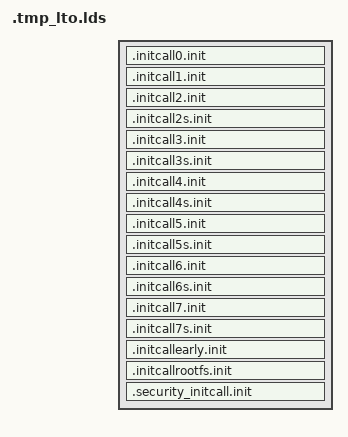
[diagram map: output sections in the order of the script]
SECTIONS {
	.initcall0.init : {
		*(.initcall0.init..69_53_init_mmap_min_addr) ;
		*(.initcall0.init..73_1865_dcc_init) ;
		*(.initcall0.init..66_347_mem_dump_init) ;
		*(.initcall0.init..71_947_init_watchdog) ;
		*(.initcall0.init..72_739_msm_restart_init) ;
		*(.initcall0.init..72_105_init_cpufreq_transition_notifier_list) ;
		*(.initcall0.init..150_868_net_ns_init) ;
	}
	.initcall1.init : {
		*(.initcall1.init..59_459_fpsimd_init) ;
		*(.initcall1.init..65_1789_enable_mrs_emulation) ;
		*(.initcall1.init..75_652_armv8_deprecated_init) ;
		*(.initcall1.init..87_953_arm64_memory_hotplug_init) ;
		*(.initcall1.init..81_1378_alloc_frozen_cpus) ;
		*(.initcall1.init..82_1425_cpu_hotplug_pm_sync_init) ;
		*(.initcall1.init..174_5366_wq_sysfs_init) ;
		*(.initcall1.init..69_271_ksysfs_init) ;
		*(.initcall1.init..66_794_pm_init) ;
		*(.initcall1.init..73_236_rcu_set_runtime_mode) ;
		*(.initcall1.init..85_813_rcu_spawn_tasks_kthread) ;
		*(.initcall1.init..60_101_init_jiffies_clocksource) ;
		*(.initcall1.init..116_4203_futex_init) ;
		*(.initcall1.init..219_5468_cgroup_wq_init) ;
		*(.initcall1.init..85_1299_cgroup1_wq_init) ;
		*(.initcall1.init..50_215_cpu_pm_init) ;
		*(.initcall1.init..68_194_cma_init_reserved_areas) ;
		*(.initcall1.init..79_395_fsnotify_init) ;
		*(.initcall1.init..138_2842_filelock_init) ;
		*(.initcall1.init..53_167_init_script_binfmt) ;
		*(.initcall1.init..87_2396_init_elf_binfmt) ;
		*(.initcall1.init..87_2396_init_compat_elf_binfmt) ;
		*(.initcall1.init..81_174_configfs_init) ;
		*(.initcall1.init..85_871_debugfs_init) ;
		*(.initcall1.init..44_481_prandom_init_early) ;
		*(.initcall1.init..116_2289_pinctrl_init) ;
		*(.initcall1.init..92_3696_gpiolib_dev_init) ;
		*(.initcall1.init..70_1041_rpm_smd_clk_init) ;
		*(.initcall1.init..97_4916_regulator_init) ;
		*(.initcall1.init..89_1814_iommu_init) ;
		*(.initcall1.init..55_249_opp_debug_init) ;
		*(.initcall1.init..65_437_dma_init_reserved_memory) ;
		*(.initcall1.init..57_183_soc_bus_register) ;
		*(.initcall1.init..67_541_register_cpufreq_notifier) ;
		*(.initcall1.init..92_2674_cpufreq_core_init) ;
		*(.initcall1.init..73_832_cpuidle_init) ;
		*(.initcall1.init..164_2684_sock_init) ;
		*(.initcall1.init..149_3118_net_inuse_init) ;
		*(.initcall1.init..135_337_net_defaults_init) ;
		*(.initcall1.init..138_1290_init_default_flow_dissectors) ;
		*(.initcall1.init..180_2777_netlink_proto_init) ;
	}
	.initcall2.init : {
		*(.initcall2.init..71_148_debug_monitors_init) ;
		*(.initcall2.init..70_362_topology_init) ;
		*(.initcall2.init..75_820_schedtune_init) ;
		*(.initcall2.init..72_298_irq_sysfs_init) ;
		*(.initcall2.init..102_7222_init_per_zone_wmark_min) ;
		*(.initcall2.init..88_242_bdi_class_init) ;
		*(.initcall2.init..76_197_mm_sysfs_init) ;
		*(.initcall2.init..82_961_ramoops_init) ;
		*(.initcall2.init..70_831_gpiolib_sysfs_init) ;
		*(.initcall2.init..70_111_pcibus_class_init) ;
		*(.initcall2.init..115_1507_pci_driver_init) ;
		*(.initcall2.init..89_675_backlight_class_init) ;
		*(.initcall2.init..77_210_amba_init) ;
		*(.initcall2.init..57_124_msm_bus_init) ;
		*(.initcall2.init..67_366_qsee_irq_init) ;
		*(.initcall2.init..66_297_regulator_stub_init) ;
		*(.initcall2.init..107_3277_tty_class_init) ;
		*(.initcall2.init..65_50_iommu_dev_init) ;
		*(.initcall2.init..58_1160_mipi_dsi_bus_init) ;
		*(.initcall2.init..86_1211_wakeup_sources_debugfs_init) ;
		*(.initcall2.init..58_2930_regmap_initcall) ;
		*(.initcall2.init..66_253_syscon_init) ;
		*(.initcall2.init..138_3629_spi_init) ;
		*(.initcall2.init..57_599_spmi_init) ;
		*(.initcall2.init..70_1293_spmi_sim_init) ;
		*(.initcall2.init..61_191_slimbus_init) ;
		*(.initcall2.init..102_1778_i2c_init) ;
		*(.initcall2.init..59_444_teo_governor_init) ;
		*(.initcall2.init..90_1609_init_lpm) ;
		*(.initcall2.init..65_129_qcom_apcs_ipc_init) ;
		*(.initcall2.init..64_173_qcom_hwspinlock_init) ;
		*(.initcall2.init..77_597_rpmsg_init) ;
		*(.initcall2.init..79_575_rpmsg_char_init) ;
		*(.initcall2.init..69_349_glink_rpm_init) ;
		*(.initcall2.init..159_2013_qrtr_proto_init) ;
		*(.initcall2.init..127_644_kobject_uevent_init) ;
	}
	.initcall2s.init : {
		*(.initcall2s.init..66_257_of_iommu_init) ;
		*(.initcall2s.init..74_1650_msm_rpm_driver_init) ;
	}
	.initcall3.init : {
		*(.initcall3.init..79_383_debug_traps_init) ;
		*(.initcall3.init..67_125_alloc_vectors_page) ;
		*(.initcall3.init..68_249_vdso_init) ;
		*(.initcall3.init..71_1045_arch_hw_breakpoint_init) ;
		*(.initcall3.init..65_688_arm64_dma_init) ;
		*(.initcall3.init..67_1036___iommu_dma_init) ;
		*(.initcall3.init..68_530_gic_init_sys) ;
		*(.initcall3.init..54_1585_trinket_pinctrl_init) ;
		*(.initcall3.init..67_353_dma_channel_table_init) ;
		*(.initcall3.init..108_1356_dma_bus_init) ;
		*(.initcall3.init..64_247_qcom_smd_rpm_init) ;
		*(.initcall3.init..66_1234_qcom_smem_init) ;
		*(.initcall3.init..59_354_qpnp_pbs_init) ;
		*(.initcall3.init..64_419_cmd_db_device_init) ;
		*(.initcall3.init..102_2014_subsys_restart_init) ;
		*(.initcall3.init..75_481_glink_probe_init) ;
		*(.initcall3.init..64_327_cx_ipeak_init) ;
		*(.initcall3.init..69_2327_qpnp_lcdb_regulator_init) ;
		*(.initcall3.init..66_184_refgen_init) ;
		*(.initcall3.init..74_2072_rpm_smd_regulator_driver_init) ;
		*(.initcall3.init..57_163_pmic_spmi_init) ;
		*(.initcall3.init..70_1386_spmi_pmic_arb_init) ;
		*(.initcall3.init..70_3095_sps_init) ;
		*(.initcall3.init..64_4596_gsi_init) ;
		*(.initcall3.init..125_3223_ipa3_usb_init) ;
		*(.initcall3.init..78_1051_qmp_init) ;
	}
	.initcall3s.init : {
		*(.initcall3s.init..67_255_deferred_probe_initcall) ;
		*(.initcall3s.init..69_525_of_platform_default_populate_init) ;
	}
	.initcall4.init : {
		*(.initcall4.init..53_232_uid_cache_init) ;
		*(.initcall4.init..65_958_param_sysfs_init) ;
		*(.initcall4.init..52_245_user_namespace_sysctl_init) ;
		*(.initcall4.init..74_306_sched_energy_init) ;
		*(.initcall4.init..53_156_cgroup_namespaces_init) ;
		*(.initcall4.init..119_420_dev_map_init) ;
		*(.initcall4.init..90_634_oom_init) ;
		*(.initcall4.init..89_259_default_bdi_init) ;
		*(.initcall4.init..76_2754_percpu_enable_async) ;
		*(.initcall4.init..94_2154_kcompactd_init) ;
		*(.initcall4.init..121_3753_init_user_reserve) ;
		*(.initcall4.init..122_3774_init_admin_reserve) ;
		*(.initcall4.init..123_3844_init_reserve_notifier) ;
		*(.initcall4.init..84_861_swap_init_sysfs) ;
		*(.initcall4.init..133_3787_swapfile_init) ;
		*(.initcall4.init..80_247_sel_ib_pkey_init) ;
		*(.initcall4.init..75_36_crypto_wq_init) ;
		*(.initcall4.init..119_296_cryptomgr_init) ;
		*(.initcall4.init..103_1397_cryptd_init) ;
		*(.initcall4.init..82_2223_init_bio) ;
		*(.initcall4.init..79_930_blk_settings_init) ;
		*(.initcall4.init..87_448_blk_ioc_init) ;
		*(.initcall4.init..80_181_blk_softirq_init) ;
		*(.initcall4.init..118_2972_blk_mq_init) ;
		*(.initcall4.init..88_1022_genhd_device_init) ;
		*(.initcall4.init..96_3835_gpiolib_debugfs_init) ;
		*(.initcall4.init..61_1108_pwm_debugfs_init) ;
		*(.initcall4.init..54_474_pwm_sysfs_init) ;
		*(.initcall4.init..79_414_pci_slot_init) ;
		*(.initcall4.init..97_1975_fbmem_init) ;
		*(.initcall4.init..67_1063_gdsc_init) ;
		*(.initcall4.init..65_1287_clk_cpu_osm_init) ;
		*(.initcall4.init..64_808_disp_cc_trinket_init) ;
		*(.initcall4.init..64_4454_gcc_trinket_init) ;
		*(.initcall4.init..64_489_gpu_cc_trinket_init) ;
		*(.initcall4.init..64_378_video_cc_trinket_init) ;
		*(.initcall4.init..65_124_cpuss_dump_init) ;
		*(.initcall4.init..60_1810_socinfo_init) ;
		*(.initcall4.init..25_381_msm_minidump_init) ;
		*(.initcall4.init..91_1707_msm_pil_init) ;
		*(.initcall4.init..65_679_mem_module_init) ;
		*(.initcall4.init..70_214_regulator_fixed_voltage_init) ;
		*(.initcall4.init..81_305_misc_init) ;
		*(.initcall4.init..104_5280_arm_smmu_init) ;
		*(.initcall4.init..83_1474_vga_arb_device_init) ;
		*(.initcall4.init..66_208_register_cpu_capacity_sysctl) ;
		*(.initcall4.init..58_347_qpnp_misc_init) ;
		*(.initcall4.init..86_638_dax_fs_init) ;
		*(.initcall4.init..69_1315_dma_buf_init) ;
		*(.initcall4.init..94_845_init_scsi) ;
		*(.initcall4.init..148_1986_phy_init) ;
		*(.initcall4.init..81_1330_usb_init) ;
		*(.initcall4.init..62_531_dual_role_class_init) ;
		*(.initcall4.init..71_383_usb_phy_generic_init) ;
		*(.initcall4.init..94_1641_usb_udc_init) ;
		*(.initcall4.init..100_1068_serio_init) ;
		*(.initcall4.init..118_2466_input_init) ;
		*(.initcall4.init..79_2489_qpnp_pon_init) ;
		*(.initcall4.init..67_474_rtc_init) ;
		*(.initcall4.init..67_329_media_devnode_init) ;
		*(.initcall4.init..78_1066_videodev_init) ;
		*(.initcall4.init..69_983_init_dvbdev) ;
		*(.initcall4.init..78_1869_rc_core_init) ;
		*(.initcall4.init..57_1121_power_supply_class_init) ;
		*(.initcall4.init..75_907_hwmon_init) ;
		*(.initcall4.init..86_4710_mmc_init) ;
		*(.initcall4.init..56_424_leds_init) ;
		*(.initcall4.init..64_469_qcom_scm_init) ;
		*(.initcall4.init..64_395_msm_ion_init) ;
		*(.initcall4.init..72_705_msm_ext_disp_init) ;
		*(.initcall4.init..79_2043_geni_se_driver_init) ;
		*(.initcall4.init..59_283_qpnp_revid_init) ;
		*(.initcall4.init..126_3990_ipa_module_init) ;
		*(.initcall4.init..83_1317_devfreq_init) ;
		*(.initcall4.init..54_151_devfreq_simple_ondemand_init) ;
		*(.initcall4.init..54_54_devfreq_performance_init) ;
		*(.initcall4.init..54_51_devfreq_powersave_init) ;
		*(.initcall4.init..56_154_devfreq_userspace_init) ;
		*(.initcall4.init..55_195_devfreq_passive_init) ;
		*(.initcall4.init..62_688_devfreq_cpufreq_init) ;
		*(.initcall4.init..72_631_msm_adreno_tz_init) ;
		*(.initcall4.init..54_125_devfreq_vbif_init) ;
		*(.initcall4.init..56_260_devfreq_gpubw_init) ;
		*(.initcall4.init..80_1859_iio_init) ;
		*(.initcall4.init..91_971_arm_pmu_hp_init) ;
		*(.initcall4.init..65_38_ras_init) ;
		*(.initcall4.init..64_1300_nvmem_init) ;
		*(.initcall4.init..54_196_sdam_init) ;
		*(.initcall4.init..57_64_init_soundcore) ;
		*(.initcall4.init..76_422_alsa_sound_init) ;
		*(.initcall4.init..151_3404_proto_init) ;
		*(.initcall4.init..280_8922_net_dev_init) ;
		*(.initcall4.init..149_3340_neigh_init) ;
		*(.initcall4.init..113_173_fib_notifier_init) ;
		*(.initcall4.init..176_1052_fib_rules_init) ;
		*(.initcall4.init..144_2088_pktsched_init) ;
		*(.initcall4.init..151_1062_tc_filter_init) ;
		*(.initcall4.init..141_1269_tc_action_init) ;
		*(.initcall4.init..128_1010_genl_init) ;
		*(.initcall4.init..138_203_ipv4_netfilter_init) ;
		*(.initcall4.init..155_2306_cipso_v4_init) ;
		*(.initcall4.init..139_838_bt_init) ;
		*(.initcall4.init..149_1397_cfg80211_init) ;
		*(.initcall4.init..106_408_wireless_nlevent_init) ;
		*(.initcall4.init..145_1537_netlbl_init) ;
		*(.initcall4.init..105_1358_rfkill_init) ;
	}
	.initcall4s.init : {
		*(.initcall4s.init..89_6852_pcie_init) ;
		*(.initcall4s.init..68_256_deferred_probe_initcall) ;
	}
	.initcall5.init : {
		*(.initcall5.init..70_72_create_debug_debugfs_entry) ;
		*(.initcall5.init..66_697_dma_debug_do_init) ;
		*(.initcall5.init..84_933_sugov_register) ;
		*(.initcall5.init..72_707_clocksource_done_booting) ;
		*(.initcall5.init..110_539_bpf_init) ;
		*(.initcall5.init..84_1243_init_pipe_fs) ;
		*(.initcall5.init..97_807_inotify_user_setup) ;
		*(.initcall5.init..169_2334_eventpoll_init) ;
		*(.initcall5.init..63_178_anon_inode_init) ;
		*(.initcall5.init..137_2818_proc_locks_init) ;
		*(.initcall5.init..95_3000_dquot_init) ;
		*(.initcall5.init..78_103_quota_init) ;
		*(.initcall5.init..51_64_proc_cmdline_init) ;
		*(.initcall5.init..73_112_proc_consoles_init) ;
		*(.initcall5.init..52_31_proc_cpuinfo_init) ;
		*(.initcall5.init..51_71_proc_devices_init) ;
		*(.initcall5.init..51_54_proc_interrupts_init) ;
		*(.initcall5.init..62_45_proc_loadavg_init) ;
		*(.initcall5.init..67_190_proc_meminfo_init) ;
		*(.initcall5.init..68_205_proc_stat_init) ;
		*(.initcall5.init..51_50_proc_uptime_init) ;
		*(.initcall5.init..51_35_proc_version_init) ;
		*(.initcall5.init..51_45_proc_softirqs_init) ;
		*(.initcall5.init..60_65_proc_kmsg_init) ;
		*(.initcall5.init..78_309_proc_page_init) ;
		*(.initcall5.init..79_277_init_ramfs_fs) ;
		*(.initcall5.init..89_764_blk_scsi_ioctl_init) ;
		*(.initcall5.init..64_736_clk_debug_trinket_init) ;
		*(.initcall5.init..73_460_mdss_pll_driver_init) ;
		*(.initcall5.init..77_1376_msm_bus_device_init_driver) ;
		*(.initcall5.init..101_962_chr_dev_init) ;
		*(.initcall5.init..86_1855_firmware_class_init) ;
		*(.initcall5.init..53_58_cpufreq_gov_performance_init) ;
		*(.initcall5.init..141_600_sysctl_core_init) ;
		*(.initcall5.init..136_526_eth_offload_init) ;
		*(.initcall5.init..146_1799_ipv4_offload_init) ;
		*(.initcall5.init..148_1929_inet_init) ;
		*(.initcall5.init..158_2984_af_unix_init) ;
		*(.initcall5.init..129_387_ipv6_offload_init) ;
	}
	.initcall5s.init : {
		*(.initcall5s.init..67_3739_pci_apply_final_quirks) ;
		*(.initcall5s.init..69_257_deferred_probe_initcall) ;
	}
	.initcall6.init : {
		*(.initcall6.init..71_391_register_kernel_offset_dumper) ;
		*(.initcall6.init..55_398_cpuinfo_regs_init) ;
		*(.initcall6.init..64_70_register_cpu_hwcaps_dumper) ;
		*(.initcall6.init..82_1316_armv8_pmu_driver_init) ;
		*(.initcall6.init..86_824_register_mem_limit_dumper) ;
		*(.initcall6.init..62_407_ptdump_init) ;
		*(.initcall6.init..88_126_cpu_feature_match_SHA1_init) ;
		*(.initcall6.init..88_156_cpu_feature_match_SHA2_init) ;
		*(.initcall6.init..112_602_ghash_ce_mod_init) ;
		*(.initcall6.init..85_240_crc32_pmull_mod_init) ;
		*(.initcall6.init..64_189_cpu_feature_match_AES_init) ;
		*(.initcall6.init..97_386_aes_mod_init) ;
		*(.initcall6.init..94_674_cpu_feature_match_AES_init) ;
		*(.initcall6.init..108_676_aes_init) ;
		*(.initcall6.init..93_185_sha256_mod_init) ;
		*(.initcall6.init..93_93_sha512_mod_init) ;
		*(.initcall6.init..81_122_chacha20_simd_mod_init) ;
		*(.initcall6.init..61_63_aes_init) ;
		*(.initcall6.init..91_477_aes_init) ;
		*(.initcall6.init..72_48_proc_execdomains_init) ;
		*(.initcall6.init..83_2318_cpuhp_sysfs_init) ;
		*(.initcall6.init..64_178_ioresources_init) ;
		*(.initcall6.init..68_200_irq_pm_init_ops) ;
		*(.initcall6.init..65_1761_timekeeping_init_ops) ;
		*(.initcall6.init..79_1061_init_clocksource_sysfs) ;
		*(.initcall6.init..64_398_init_timer_list_procfs) ;
		*(.initcall6.init..73_931_alarmtimer_init) ;
		*(.initcall6.init..73_284_init_posix_timers) ;
		*(.initcall6.init..79_762_clockevents_init_sysfs) ;
		*(.initcall6.init..59_319_sched_clock_syscore_init) ;
		*(.initcall6.init..109_710_kallsyms_init) ;
		*(.initcall6.init..63_92_ikconfig_init) ;
		*(.initcall6.init..119_1242_seccomp_sysctl_init) ;
		*(.initcall6.init..44_148_utsname_sysctl_init) ;
		*(.initcall6.init..264_11758_perf_event_sysfs_init) ;
		*(.initcall6.init..49_133_system_trusted_keyring_init) ;
		*(.initcall6.init..108_3874_kswapd_init) ;
		*(.initcall6.init..78_2131_extfrag_debug_init) ;
		*(.initcall6.init..75_185_mm_compute_batch_init) ;
		*(.initcall6.init..84_576_workingset_init) ;
		*(.initcall6.init..113_2892_proc_vmalloc_init) ;
		*(.initcall6.init..73_1788_memblock_init_debugfs) ;
		*(.initcall6.init..109_2845_procswaps_init) ;
		*(.initcall6.init..121_5932_slab_sysfs_init) ;
		*(.initcall6.init..100_2633_zs_init) ;
		*(.initcall6.init..75_1145_init_z3fold) ;
		*(.initcall6.init..83_252_process_reclaim_init) ;
		*(.initcall6.init..98_1034_fcntl_init) ;
		*(.initcall6.init..72_277_proc_filesystems_init) ;
		*(.initcall6.init..90_2077_start_dirtytime_writeback) ;
		*(.initcall6.init..82_467_blkdev_init) ;
		*(.initcall6.init..79_1472_dio_init) ;
		*(.initcall6.init..59_396_dnotify_init) ;
		*(.initcall6.init..86_274_aio_setup) ;
		*(.initcall6.init..91_488_fscrypt_init) ;
		*(.initcall6.init..241_1645_init_sys32_ioctl) ;
		*(.initcall6.init..65_463_mbcache_init) ;
		*(.initcall6.init..55_437_init_v2_quota_format) ;
		*(.initcall6.init..81_642_init_devpts_fs) ;
		*(.initcall6.init..156_6099_ext4_init_fs) ;
		*(.initcall6.init..91_2724_journal_init) ;
		*(.initcall6.init..85_1954_init_fat_fs) ;
		*(.initcall6.init..79_1092_init_vfat_fs) ;
		*(.initcall6.init..80_858_init_exfat_fs) ;
		*(.initcall6.init..107_909_ecryptfs_init) ;
		*(.initcall6.init..78_518_init_sdcardfs_fs) ;
		*(.initcall6.init..50_384_init_nls_cp437) ;
		*(.initcall6.init..50_254_init_nls_iso8859_1) ;
		*(.initcall6.init..50_65_init_nls_utf8) ;
		*(.initcall6.init..87_3209_init_ntfs_fs) ;
		*(.initcall6.init..96_1399_fuse_init) ;
		*(.initcall6.init..70_1292_ovl_init) ;
		*(.initcall6.init..94_3667_init_f2fs_fs) ;
		*(.initcall6.init..83_543_init_pstore_fs) ;
		*(.initcall6.init..64_79_key_proc_init) ;
		*(.initcall6.init..173_6825_selinux_nf_ip_init) ;
		*(.initcall6.init..147_1934_init_sel_fs) ;
		*(.initcall6.init..78_124_selnl_init) ;
		*(.initcall6.init..107_291_sel_netif_init) ;
		*(.initcall6.init..140_318_sel_netnode_init) ;
		*(.initcall6.init..140_252_sel_netport_init) ;
		*(.initcall6.init..85_563_pfk_init) ;
		*(.initcall6.init..60_916_pfk_kc_pre_init) ;
		*(.initcall6.init..135_1083_crypto_algapi_init) ;
		*(.initcall6.init..95_220_seqiv_module_init) ;
		*(.initcall6.init..95_182_echainiv_module_init) ;
		*(.initcall6.init..80_395_rsa_init) ;
		*(.initcall6.init..85_316_crypto_cmac_module_init) ;
		*(.initcall6.init..93_271_hmac_module_init) ;
		*(.initcall6.init..85_286_crypto_xcbc_module_init) ;
		*(.initcall6.init..97_217_crypto_null_mod_init) ;
		*(.initcall6.init..85_253_md4_mod_init) ;
		*(.initcall6.init..85_265_md5_mod_init) ;
		*(.initcall6.init..85_95_sha1_generic_mod_init) ;
		*(.initcall6.init..85_304_sha256_generic_mod_init) ;
		*(.initcall6.init..85_204_sha512_generic_mod_init) ;
		*(.initcall6.init..75_183_crypto_ecb_module_init) ;
		*(.initcall6.init..81_204_crypto_cbc_module_init) ;
		*(.initcall6.init..89_424_crypto_cts_module_init) ;
		*(.initcall6.init..89_615_crypto_module_init) ;
		*(.initcall6.init..81_481_crypto_ctr_module_init) ;
		*(.initcall6.init..107_1295_crypto_gcm_module_init) ;
		*(.initcall6.init..61_996_des_generic_mod_init) ;
		*(.initcall6.init..61_209_twofish_mod_init) ;
		*(.initcall6.init..61_1473_aes_init) ;
		*(.initcall6.init..75_163_arc4_init) ;
		*(.initcall6.init..81_206_chacha_generic_mod_init) ;
		*(.initcall6.init..66_337_deflate_mod_init) ;
		*(.initcall6.init..85_168_crc32c_mod_init) ;
		*(.initcall6.init..85_154_crc32_mod_init) ;
		*(.initcall6.init..131_511_crypto_authenc_module_init) ;
		*(.initcall6.init..130_526_crypto_authenc_esn_module_init) ;
		*(.initcall6.init..66_170_lzo_mod_init) ;
		*(.initcall6.init..66_170_lzorle_mod_init) ;
		*(.initcall6.init..63_168_lz4_mod_init) ;
		*(.initcall6.init..63_169_lz4hc_mod_init) ;
		*(.initcall6.init..81_475_prng_mod_init) ;
		*(.initcall6.init..104_2063_drbg_init) ;
		*(.initcall6.init..76_201_jent_mod_init) ;
		*(.initcall6.init..86_165_ghash_mod_init) ;
		*(.initcall6.init..66_260_zstd_mod_init) ;
		*(.initcall6.init..85_1132_streebog_mod_init) ;
		*(.initcall6.init..77_166_ecdh_init) ;
		*(.initcall6.init..58_612_asymmetric_key_init) ;
		*(.initcall6.init..68_274_x509_key_init) ;
		*(.initcall6.init..104_1337_proc_genhd_init) ;
		*(.initcall6.init..81_118_noop_init) ;
		*(.initcall6.init..104_4987_cfq_init) ;
		*(.initcall6.init..65_74_libcrc32c_mod_init) ;
		*(.initcall6.init..51_156_init_kmp) ;
		*(.initcall6.init..51_206_init_bm) ;
		*(.initcall6.init..51_340_init_fsm) ;
		*(.initcall6.init..56_239_percpu_counter_startup) ;
		*(.initcall6.init..63_171_sg_pool_init) ;
		*(.initcall6.init..64_407_qcom_ebi2_driver_init) ;
		*(.initcall6.init..62_1016_phy_core_init) ;
		*(.initcall6.init..64_299_ufs_qcom_phy_qmp_14nm_driver_init) ;
		*(.initcall6.init..64_232_ufs_qcom_phy_qmp_v3_driver_init) ;
		*(.initcall6.init..64_155_ufs_qcom_phy_qrbtc_sdm845_driver_init) ;
		*(.initcall6.init..64_246_ufs_qcom_phy_qmp_v3_660_driver_init) ;
		*(.initcall6.init..64_291_ufs_qcom_phy_qmp_v4_driver_init) ;
		*(.initcall6.init..67_1204_pmic_gpio_driver_init) ;
		*(.initcall6.init..67_943_pmic_mpp_driver_init) ;
		*(.initcall6.init..66_1725_qpnp_lpg_driver_init) ;
		*(.initcall6.init..76_463_pci_proc_init) ;
		*(.initcall6.init..75_115_genericbl_driver_init) ;
		*(.initcall6.init..83_2415_wled_driver_init) ;
		*(.initcall6.init..80_1072_amba_clcdfb_init) ;
		*(.initcall6.init..81_539_vfb_init) ;
		*(.initcall6.init..68_250_of_fixed_factor_clk_driver_init) ;
		*(.initcall6.init..68_240_of_fixed_clk_driver_init) ;
		*(.initcall6.init..72_299_gpio_clk_driver_init) ;
		*(.initcall6.init..65_317_spmi_pmic_clkdiv_driver_init) ;
		*(.initcall6.init..75_3155_gpi_init) ;
		*(.initcall6.init..86_789_qcom_smp2p_driver_init) ;
		*(.initcall6.init..114_4100_icnss_initialize) ;
		*(.initcall6.init..65_962_memshare_pdriver_init) ;
		*(.initcall6.init..66_963_memshare_pchild_init) ;
		*(.initcall6.init..84_1270_pil_tz_init) ;
		*(.initcall6.init..54_262_cdsp_loader_init) ;
		*(.initcall6.init..87_2018_smcinvoke_init) ;
		*(.initcall6.init..50_148_microdump_init) ;
		*(.initcall6.init..75_709_msm_eud_init) ;
		*(.initcall6.init..73_303_glink_ssr_driver_init) ;
		*(.initcall6.init..97_895_glink_pkt_init) ;
		*(.initcall6.init..60_453_fsa4480_init) ;
		*(.initcall6.init..69_132_smp2p_sleepstate_init) ;
		*(.initcall6.init..65_1153_cdsprm_init) ;
		*(.initcall6.init..74_74_n_null_init) ;
		*(.initcall6.init..86_968_pty_init) ;
		*(.initcall6.init..120_3126_msm_geni_serial_init) ;
		*(.initcall6.init..83_596_hwrng_modinit) ;
		*(.initcall6.init..83_491_msm_rng_init) ;
		*(.initcall6.init..66_92_cavium_rng_pf_driver_init) ;
		*(.initcall6.init..67_100_cavium_rng_vf_driver_init) ;
		*(.initcall6.init..96_4598_diagchar_init) ;
		*(.initcall6.init..69_925_diag_rpmsg_drv_init) ;
		*(.initcall6.init..66_145_io_pgtable_init) ;
		*(.initcall6.init..70_2579_iommu_debug_init) ;
		*(.initcall6.init..83_59_drm_kms_helper_init) ;
		*(.initcall6.init..100_1007_drm_core_init) ;
		*(.initcall6.init..91_363_dp_sim_register) ;
		*(.initcall6.init..110_1954_sde_rsc_register) ;
		*(.initcall6.init..115_530_sde_kmem_pool_init) ;
		*(.initcall6.init..128_8204_dsi_display_register) ;
		*(.initcall6.init..128_841_sde_wb_register) ;
		*(.initcall6.init..141_2234_msm_drm_register) ;
		*(.initcall6.init..106_5271_kgsl_core_init) ;
		*(.initcall6.init..116_4101_kgsl_3d_init) ;
		*(.initcall6.init..65_136_topology_sysfs_init) ;
		*(.initcall6.init..53_676_cacheinfo_sysfs_init) ;
		*(.initcall6.init..104_619_brd_init) ;
		*(.initcall6.init..92_2241_loop_init) ;
		*(.initcall6.init..93_2264_zram_init) ;
		*(.initcall6.init..64_352_msm_hdcp_init) ;
		*(.initcall6.init..265_9537_qseecom_init) ;
		*(.initcall6.init..50_114_force_fast_charge_init) ;
		*(.initcall6.init..70_742_i2c_pmic_driver_init) ;
		*(.initcall6.init..75_1520_nqx_dev_init) ;
		*(.initcall6.init..247_2342_qcedev_init) ;
		*(.initcall6.init..167_5589__qcrypto_init) ;
		*(.initcall6.init..89_1837_qcom_ice_driver_init) ;
		*(.initcall6.init..126_3700_init_sd) ;
		*(.initcall6.init..142_2745_init_sg) ;
		*(.initcall6.init..102_1039_init_ch_module) ;
		*(.initcall6.init..82_889_spidev_init) ;
		*(.initcall6.init..74_1924_spi_geni_driver_init) ;
		*(.initcall6.init..209_4939_bonding_init) ;
		*(.initcall6.init..108_458_dummy_init_module) ;
		*(.initcall6.init..103_165_net_olddevs_init) ;
		*(.initcall6.init..84_324_fixed_mdio_bus_init) ;
		*(.initcall6.init..175_2996_tun_init) ;
		*(.initcall6.init..130_771_rmnet_init) ;
		*(.initcall6.init..171_3336_ppp_init) ;
		*(.initcall6.init..127_1026_ppp_async_init) ;
		*(.initcall6.init..50_1167_bsdcomp_init) ;
		*(.initcall6.init..50_635_deflate_init) ;
		*(.initcall6.init..77_758_ppp_mppe_init) ;
		*(.initcall6.init..123_736_ppp_sync_init) ;
		*(.initcall6.init..125_157_pppox_init) ;
		*(.initcall6.init..130_1222_pppoe_init) ;
		*(.initcall6.init..138_695_pptp_init_module) ;
		*(.initcall6.init..125_446_pppolac_init) ;
		*(.initcall6.init..124_427_pppopns_init) ;
		*(.initcall6.init..53_383_wcnss_pre_alloc_init) ;
		*(.initcall6.init..104_632_cnss_utils_init) ;
		*(.initcall6.init..79_205_cld80211_init) ;
		*(.initcall6.init..147_5341_rtl8152_driver_init) ;
		*(.initcall6.init..108_1387_asix_driver_init) ;
		*(.initcall6.init..108_1796_ax88179_178a_driver_init) ;
		*(.initcall6.init..107_963_cdc_driver_init) ;
		*(.initcall6.init..106_531_net1080_driver_init) ;
		*(.initcall6.init..106_365_cdc_subset_driver_init) ;
		*(.initcall6.init..104_381_zaurus_driver_init) ;
		*(.initcall6.init..111_2204_usbnet_init) ;
		*(.initcall6.init..129_1805_cdc_ncm_driver_init) ;
		*(.initcall6.init..77_1042_uio_init) ;
		*(.initcall6.init..65_238_msm_sharedmem_init) ;
		*(.initcall6.init..66_151_qcusb_emu_phy_driver_init) ;
		*(.initcall6.init..76_1290_msm_ssphy_qmp_driver_init) ;
		*(.initcall6.init..85_1405_qusb_phy_driver_init) ;
		*(.initcall6.init..73_1189_qusb_phy_driver_init) ;
		*(.initcall6.init..72_938_msm_hsphy_driver_init) ;
		*(.initcall6.init..71_1667_dwc3_driver_init) ;
		*(.initcall6.init..65_213_dwc3_of_simple_driver_init) ;
		*(.initcall6.init..112_4908_dwc3_msm_init) ;
		*(.initcall6.init..69_300_isp1760_init) ;
		*(.initcall6.init..107_1400_ehci_hcd_init) ;
		*(.initcall6.init..71_436_ehci_pci_init) ;
		*(.initcall6.init..71_444_ehci_platform_init) ;
		*(.initcall6.init..96_1354_ohci_hcd_mod_init) ;
		*(.initcall6.init..72_321_ohci_pci_init) ;
		*(.initcall6.init..70_401_ohci_platform_init) ;
		*(.initcall6.init..98_5312_xhci_hcd_init) ;
		*(.initcall6.init..73_567_xhci_pci_init) ;
		*(.initcall6.init..69_584_xhci_plat_init) ;
		*(.initcall6.init..90_1175_usb_storage_driver_init) ;
		*(.initcall6.init..60_353_ehset_driver_init) ;
		*(.initcall6.init..65_494_lvs_driver_init) ;
		*(.initcall6.init..131_1948_gadget_cfs_init) ;
		*(.initcall6.init..117_1796_ncmmod_init) ;
		*(.initcall6.init..104_3456_mass_storagemod_init) ;
		*(.initcall6.init..102_3737_ffsmod_init) ;
		*(.initcall6.init..77_1416_midimod_init) ;
		*(.initcall6.init..81_1137_hidmod_init) ;
		*(.initcall6.init..83_1936_mtp_init) ;
		*(.initcall6.init..70_36_ptpmod_init) ;
		*(.initcall6.init..75_1070_audio_sourcemod_init) ;
		*(.initcall6.init..84_1439_accessorymod_init) ;
		*(.initcall6.init..94_1097_diag_init) ;
		*(.initcall6.init..98_2167_csermod_init) ;
		*(.initcall6.init..81_1246_ccidmod_init) ;
		*(.initcall6.init..162_3888_fgsi_init) ;
		*(.initcall6.init..90_1220_usb_qdss_init) ;
		*(.initcall6.init..70_4720_usbpd_init) ;
		*(.initcall6.init..67_933_pdphy_driver_init) ;
		*(.initcall6.init..57_213_input_leds_init) ;
		*(.initcall6.init..86_1462_evdev_init) ;
		*(.initcall6.init..75_1820_atkbd_init) ;
		*(.initcall6.init..64_237_tp_info_init) ;
		*(.initcall6.init..72_215_tp_selftest_init) ;
		*(.initcall6.init..64_214_tp_gesture_init) ;
		*(.initcall6.init..82_2850_nvt_driver_init) ;
		*(.initcall6.init..83_2008_fts_ts_init) ;
		*(.initcall6.init..84_274_himax_hx83112_init) ;
		*(.initcall6.init..86_964_himax_common_init) ;
		*(.initcall6.init..130_3703_syna_tcm_module_init) ;
		*(.initcall6.init..55_1267_touch_module_init) ;
		*(.initcall6.init..68_702_device_module_init) ;
		*(.initcall6.init..68_1933_testing_module_init) ;
		*(.initcall6.init..55_2181_reflash_module_init) ;
		*(.initcall6.init..55_893_recovery_module_init) ;
		*(.initcall6.init..68_1007_zeroflash_module_init) ;
		*(.initcall6.init..61_559_diag_module_init) ;
		*(.initcall6.init..67_1088_uinput_misc_init) ;
		*(.initcall6.init..80_714_fpc1020_init) ;
		*(.initcall6.init..84_883_gf_init) ;
		*(.initcall6.init..72_762_qpnp_rtc_init) ;
		*(.initcall6.init..77_683_i2c_dev_init) ;
		*(.initcall6.init..70_1121_geni_i2c_driver_init) ;
		*(.initcall6.init..72_518_ir_kbd_driver_init) ;
		*(.initcall6.init..55_86_init_rc_map_adstech_dvb_t_pci) ;
		*(.initcall6.init..55_65_init_rc_map_alink_dtu_m) ;
		*(.initcall6.init..55_90_init_rc_map_anysee) ;
		*(.initcall6.init..55_77_init_rc_map_apac_viewcomp) ;
		*(.initcall6.init..55_88_init_rc_map_asus_pc39) ;
		*(.initcall6.init..55_87_init_rc_map_asus_ps3_100) ;
		*(.initcall6.init..55_66_init_rc_map_ati_tv_wonder_hd_600) ;
		*(.initcall6.init..55_134_init_rc_map_ati_x10) ;
		*(.initcall6.init..55_72_init_rc_map_avermedia_a16d) ;
		*(.initcall6.init..55_83_init_rc_map_avermedia) ;
		*(.initcall6.init..55_94_init_rc_map_avermedia_cardbus) ;
		*(.initcall6.init..55_75_init_rc_map_avermedia_dvbt) ;
		*(.initcall6.init..55_144_init_rc_map_avermedia_m135a) ;
		*(.initcall6.init..55_92_init_rc_map_avermedia_m733a_rm_k6) ;
		*(.initcall6.init..55_76_init_rc_map_avermedia_rm_ks) ;
		*(.initcall6.init..55_82_init_rc_map_avertv_303) ;
		*(.initcall6.init..55_99_init_rc_map_azurewave_ad_tu700) ;
		*(.initcall6.init..55_138_init_rc_map_behold) ;
		*(.initcall6.init..55_105_init_rc_map_behold_columbus) ;
		*(.initcall6.init..55_90_init_rc_map_budget_ci_old) ;
		*(.initcall6.init..55_178_init_rc_map_cec) ;
		*(.initcall6.init..55_81_init_rc_map_cinergy_1400) ;
		*(.initcall6.init..55_75_init_rc_map_cinergy) ;
		*(.initcall6.init..55_71_init_rc_map_d680_dmb) ;
		*(.initcall6.init..55_78_init_rc_map_delock_61959) ;
		*(.initcall6.init..55_121_init_rc_map) ;
		*(.initcall6.init..55_232_init_rc_map) ;
		*(.initcall6.init..55_95_init_rc_map_digitalnow_tinytwin) ;
		*(.initcall6.init..55_79_init_rc_map_digittrade) ;
		*(.initcall6.init..55_73_init_rc_map_dm1105_nec) ;
		*(.initcall6.init..55_75_init_rc_map_dntv_live_dvb_t) ;
		*(.initcall6.init..55_94_init_rc_map_dntv_live_dvbt_pro) ;
		*(.initcall6.init..55_55_init_rc_map_dtt200u) ;
		*(.initcall6.init..55_74_init_rc_map_rc5_dvbsky) ;
		*(.initcall6.init..55_81_init_rc_map_dvico_mce) ;
		*(.initcall6.init..55_72_init_rc_map_dvico_portable) ;
		*(.initcall6.init..55_66_init_rc_map_em_terratec) ;
		*(.initcall6.init..55_87_init_rc_map_encore_enltv2) ;
		*(.initcall6.init..55_109_init_rc_map_encore_enltv) ;
		*(.initcall6.init..55_78_init_rc_map_encore_enltv_fm53) ;
		*(.initcall6.init..55_58_init_rc_map_evga_indtube) ;
		*(.initcall6.init..55_93_init_rc_map_eztv) ;
		*(.initcall6.init..55_74_init_rc_map_flydvb) ;
		*(.initcall6.init..55_67_init_rc_map_flyvideo) ;
		*(.initcall6.init..55_95_init_rc_map_fusionhdtv_mce) ;
		*(.initcall6.init..55_78_init_rc_map_gadmei_rm008z) ;
		*(.initcall6.init..55_51_init_rc_map_geekbox) ;
		*(.initcall6.init..55_81_init_rc_map_genius_tvgo_a11mce) ;
		*(.initcall6.init..55_76_init_rc_map_gotview7135) ;
		*(.initcall6.init..55_139_init_rc_map_imon_mce) ;
		*(.initcall6.init..55_153_init_rc_map_imon_pad) ;
		*(.initcall6.init..55_85_init_rc_map_iodata_bctv7e) ;
		*(.initcall6.init..55_91_init_rc_it913x_v1_map) ;
		*(.initcall6.init..55_90_init_rc_it913x_v2_map) ;
		*(.initcall6.init..55_84_init_rc_map_kaiomy) ;
		*(.initcall6.init..55_80_init_rc_map_kworld_315u) ;
		*(.initcall6.init..55_98_init_rc_map_kworld_pc150u) ;
		*(.initcall6.init..55_96_init_rc_map_kworld_plus_tv_analog) ;
		*(.initcall6.init..55_96_init_rc_map_leadtek_y04g0051) ;
		*(.initcall6.init..55_107_init_rc_lme2510_map) ;
		*(.initcall6.init..55_131_init_rc_map_manli) ;
		*(.initcall6.init..55_113_init_rc_map_medion_x10) ;
		*(.initcall6.init..55_118_init_rc_map_medion_x10_digitainer) ;
		*(.initcall6.init..55_103_init_rc_map_medion_x10_or2x) ;
		*(.initcall6.init..55_64_init_rc_map_msi_digivox_ii) ;
		*(.initcall6.init..55_82_init_rc_map_msi_digivox_iii) ;
		*(.initcall6.init..55_66_init_rc_map_msi_tvanywhere) ;
		*(.initcall6.init..55_120_init_rc_map_msi_tvanywhere_plus) ;
		*(.initcall6.init..55_93_init_rc_map_nebula) ;
		*(.initcall6.init..55_154_init_rc_map_nec_terratec_cinergy_xs) ;
		*(.initcall6.init..55_82_init_rc_map_norwood) ;
		*(.initcall6.init..55_77_init_rc_map_npgtech) ;
		*(.initcall6.init..55_77_init_rc_map_pctv_sedna) ;
		*(.initcall6.init..55_91_init_rc_map_pinnacle_color) ;
		*(.initcall6.init..55_86_init_rc_map_pinnacle_grey) ;
		*(.initcall6.init..55_67_init_rc_map_pinnacle_pctv_hd) ;
		*(.initcall6.init..55_79_init_rc_map_pixelview) ;
		*(.initcall6.init..55_80_init_rc_map_pixelview) ;
		*(.initcall6.init..55_74_init_rc_map_pixelview) ;
		*(.initcall6.init..55_80_init_rc_map_pixelview_new) ;
		*(.initcall6.init..55_78_init_rc_map_powercolor_real_angel) ;
		*(.initcall6.init..55_66_init_rc_map_proteus_2309) ;
		*(.initcall6.init..55_78_init_rc_map_purpletv) ;
		*(.initcall6.init..55_75_init_rc_map_pv951) ;
		*(.initcall6.init..55_289_init_rc_map_rc5_hauppauge_new) ;
		*(.initcall6.init..55_116_init_rc_map_rc6_mce) ;
		*(.initcall6.init..55_75_init_rc_map_real_audio_220_32_keys) ;
		*(.initcall6.init..55_82_init_rc_map_reddo) ;
		*(.initcall6.init..55_103_init_rc_map_snapstream_firefly) ;
		*(.initcall6.init..55_77_init_rc_map_streamzap) ;
		*(.initcall6.init..55_72_init_rc_map_tbs_nec) ;
		*(.initcall6.init..55_73_init_rc_map) ;
		*(.initcall6.init..55_86_init_rc_map) ;
		*(.initcall6.init..55_85_init_rc_map_terratec_cinergy_c_pci) ;
		*(.initcall6.init..55_83_init_rc_map_terratec_cinergy_s2_hd) ;
		*(.initcall6.init..55_89_init_rc_map_terratec_cinergy_xs) ;
		*(.initcall6.init..55_76_init_rc_map_terratec_slim) ;
		*(.initcall6.init..55_69_init_rc_map_terratec_slim_2) ;
		*(.initcall6.init..55_85_init_rc_map_tevii_nec) ;
		*(.initcall6.init..55_95_init_rc_map_tivo) ;
		*(.initcall6.init..55_82_init_rc_map_total_media_in_hand) ;
		*(.initcall6.init..55_82_init_rc_map_total_media_in_hand_02) ;
		*(.initcall6.init..55_77_init_rc_map_trekstor) ;
		*(.initcall6.init..55_79_init_rc_map_tt_1500) ;
		*(.initcall6.init..55_95_init_rc_map_twinhan_dtv_cab_ci) ;
		*(.initcall6.init..55_84_init_rc_map_twinhan_vp1027) ;
		*(.initcall6.init..55_89_init_rc_map_videomate_k100) ;
		*(.initcall6.init..55_82_init_rc_map_videomate_s350) ;
		*(.initcall6.init..55_84_init_rc_map_videomate_tv_pvr) ;
		*(.initcall6.init..55_99_init_rc_map_winfast) ;
		*(.initcall6.init..55_79_init_rc_map_winfast_usbii_deluxe) ;
		*(.initcall6.init..55_71_init_rc_map_su3000) ;
		*(.initcall6.init..55_75_init_rc_map_zx_irdec) ;
		*(.initcall6.init..66_282_ir_nec_decode_init) ;
		*(.initcall6.init..66_300_ir_rc5_decode_init) ;
		*(.initcall6.init..66_431_ir_rc6_decode_init) ;
		*(.initcall6.init..66_230_ir_jvc_decode_init) ;
		*(.initcall6.init..66_239_ir_sony_decode_init) ;
		*(.initcall6.init..66_236_ir_sanyo_decode_init) ;
		*(.initcall6.init..66_244_ir_sharp_decode_init) ;
		*(.initcall6.init..66_494_ir_mce_kbd_decode_init) ;
		*(.initcall6.init..66_216_ir_xmp_decode_init) ;
		*(.initcall6.init..99_3666_sde_rotator_init_module) ;
		*(.initcall6.init..71_793_sde_smmu_driver_init) ;
		*(.initcall6.init..78_938_msm_vidc_init) ;
		*(.initcall6.init..76_1007_msm_vidc_bw_gov_init) ;
		*(.initcall6.init..76_965_msm_vidc_ar50_bw_gov_init) ;
		*(.initcall6.init..87_2322_cam_smmu_init_module) ;
		*(.initcall6.init..148_1487_msm_init) ;
		*(.initcall6.init..81_2239_msm_cci_init_module) ;
		*(.initcall6.init..80_2532_msm_csiphy_init_module) ;
		*(.initcall6.init..80_1537_msm_csid_init_module) ;
		*(.initcall6.init..80_2154_msm_actuator_init_module) ;
		*(.initcall6.init..80_2096_msm_eeprom_init_module) ;
		*(.initcall6.init..80_1110_msm_ois_init_module) ;
		*(.initcall6.init..80_1417_msm_flash_init_module) ;
		*(.initcall6.init..80_458_msm_ir_led_init_module) ;
		*(.initcall6.init..80_657_msm_ir_cut_init_module) ;
		*(.initcall6.init..80_624_msm_laser_led_init_module) ;
		*(.initcall6.init..80_222_msm_sensor_init_module) ;
		*(.initcall6.init..80_1885_msm_sensor_driver_init) ;
		*(.initcall6.init..122_4885_msm_cpp_init_module) ;
		*(.initcall6.init..80_672_msm_vfe47_init_module) ;
		*(.initcall6.init..80_3204_msm_vfe47_init_module) ;
		*(.initcall6.init..80_2041_msm_vfe46_init_module) ;
		*(.initcall6.init..80_1972_msm_vfe44_init_module) ;
		*(.initcall6.init..80_2407_msm_vfe40_init_module) ;
		*(.initcall6.init..79_2147_msm_ispif_init_module) ;
		*(.initcall6.init..81_319_msm_jpeg_driver_init) ;
		*(.initcall6.init..86_1512_msm_jpegdma_init_module) ;
		*(.initcall6.init..104_944_msm_buf_mngr_init) ;
		*(.initcall6.init..80_1493_msm_fd_init_module) ;
		*(.initcall6.init..64_109_xgene_reboot_init) ;
		*(.initcall6.init..64_91_syscon_reboot_driver_init) ;
		*(.initcall6.init..76_4701_qpnp_qg_driver_init) ;
		*(.initcall6.init..70_1707_smb1355_driver_init) ;
		*(.initcall6.init..72_3780_smb5_driver_init) ;
		*(.initcall6.init..78_1013_smb1390_driver_init) ;
		*(.initcall6.init..100_3016_dm_init) ;
		*(.initcall6.init..110_1987_dm_bufio_init) ;
		*(.initcall6.init..133_3145_dm_crypt_init) ;
		*(.initcall6.init..79_217_dm_default_key_init) ;
		*(.initcall6.init..91_1275_dm_verity_init) ;
		*(.initcall6.init..70_779_bluetooth_power_init) ;
		*(.initcall6.init..76_617_btfm_slim_init) ;
		*(.initcall6.init..53_53_cpufreq_gov_powersave_init) ;
		*(.initcall6.init..50_170_arm_idle_init) ;
		*(.initcall6.init..81_160_mmc_pwrseq_simple_driver_init) ;
		*(.initcall6.init..80_120_mmc_pwrseq_emmc_driver_init) ;
		*(.initcall6.init..101_4431_mmc_blk_init) ;
		*(.initcall6.init..80_5130_sdhci_drv_init) ;
		*(.initcall6.init..78_270_sdhci_pltfm_drv_init) ;
		*(.initcall6.init..88_5611_sdhci_msm_driver_init) ;
		*(.initcall6.init..59_465_sgm_i2c_driver_init) ;
		*(.initcall6.init..73_2503_qpnp_haptics_driver_init) ;
		*(.initcall6.init..68_647_qpnp_tri_led_driver_init) ;
		*(.initcall6.init..64_560_qpnp_vibrator_ldo_driver_init) ;
		*(.initcall6.init..54_125_timer_trig_init) ;
		*(.initcall6.init..89_3217_hid_init) ;
		*(.initcall6.init..67_797_uhid_misc_init) ;
		*(.initcall6.init..55_37_hid_generic_init) ;
		*(.initcall6.init..61_610_apple_driver_init) ;
		*(.initcall6.init..55_329_dr_driver_init) ;
		*(.initcall6.init..55_93_elecom_driver_init) ;
		*(.initcall6.init..64_600_magicmouse_driver_init) ;
		*(.initcall6.init..55_297_ms_driver_init) ;
		*(.initcall6.init..65_1777_mt_driver_init) ;
		*(.initcall6.init..55_226_plantronics_driver_init) ;
		*(.initcall6.init..69_2956_sony_init) ;
		*(.initcall6.init..100_1686_hid_init) ;
		*(.initcall6.init..94_931_ashmem_init) ;
		*(.initcall6.init..150_16643_hdd_module_init) ;
		*(.initcall6.init..70_1486_init) ;
		*(.initcall6.init..74_1297_bimc_bwmon_driver_init) ;
		*(.initcall6.init..78_392_arm_memlat_mon_driver_init) ;
		*(.initcall6.init..71_617_msmcci_hwmon_driver_init) ;
		*(.initcall6.init..67_415_m4m_hwmon_driver_init) ;
		*(.initcall6.init..73_291_devbw_driver_init) ;
		*(.initcall6.init..72_219_devfreq_clock_driver_init) ;
		*(.initcall6.init..60_1467_extcon_class_init) ;
		*(.initcall6.init..69_328_usb_extcon_driver_init) ;
		*(.initcall6.init..65_1151_adc_driver_init) ;
		*(.initcall6.init..80_1195_stm_core_init) ;
		*(.initcall6.init..181_6187_binder_init) ;
		*(.initcall6.init..64_87_qfprom_driver_init) ;
		*(.initcall6.init..65_463_sensors_ssc_init) ;
		*(.initcall6.init..52_77_kernelsu_init) ;
		*(.initcall6.init..92_550_alsa_hwdep_init) ;
		*(.initcall6.init..130_2198_alsa_timer_init) ;
		*(.initcall6.init..89_1304_alsa_pcm_init) ;
		*(.initcall6.init..113_1838_alsa_rawmidi_init) ;
		*(.initcall6.init..67_1255_snd_compress_init) ;
		*(.initcall6.init..108_969_usb_audio_driver_init) ;
		*(.initcall6.init..72_1440_uaudio_qmi_plat_init) ;
		*(.initcall6.init..194_4494_snd_soc_init) ;
		*(.initcall6.init..86_821_hdmi_codec_driver_init) ;
		*(.initcall6.init..67_432_wcd_pinctrl_driver_init) ;
		*(.initcall6.init..67_1124_soundwire_init) ;
		*(.initcall6.init..107_2752_swrm_init) ;
		*(.initcall6.init..52_72_audio_native_init) ;
		*(.initcall6.init..50_58_audio_q6_init) ;
		*(.initcall6.init..65_2463_usf_init) ;
		*(.initcall6.init..54_353_adsp_loader_init) ;
		*(.initcall6.init..50_174_audio_pdr_late_init) ;
		*(.initcall6.init..52_634_audio_notifier_init) ;
		*(.initcall6.init..65_1250_apr_driver_init) ;
		*(.initcall6.init..65_778_wdsp_glink_init) ;
		*(.initcall6.init..73_1006_bolero_drv_init) ;
		*(.initcall6.init..73_3094_wsa_macro_driver_init) ;
		*(.initcall6.init..76_1666_va_macro_driver_init) ;
		*(.initcall6.init..77_1988_tx_macro_driver_init) ;
		*(.initcall6.init..73_3744_rx_macro_driver_init) ;
		*(.initcall6.init..115_11290_tavil_codec_driver_init) ;
		*(.initcall6.init..76_2894_wcd937x_codec_driver_init) ;
		*(.initcall6.init..58_148_wcd937x_slave_init) ;
		*(.initcall6.init..79_3057_max98927_i2c_driver_init) ;
		*(.initcall6.init..81_966_tas2562_i2c_driver_init) ;
		*(.initcall6.init..67_44_wcd9xxx_core_init) ;
		*(.initcall6.init..54_35_wcd9xxx_soc_init) ;
		*(.initcall6.init..114_14390_tasha_codec_driver_init) ;
		*(.initcall6.init..83_1645_wsa881x_codec_init) ;
		*(.initcall6.init..72_79_msm_stub_init) ;
		*(.initcall6.init..68_1576_wcd_spi_driver_init) ;
		*(.initcall6.init..82_2310_mbhc_init) ;
		*(.initcall6.init..72_759_msm_ext_disp_audio_codec_rx_init) ;
		*(.initcall6.init..50_65_audio_platform_init) ;
		*(.initcall6.init..81_9297_sm6150_asoc_machine_driver_init) ;
		*(.initcall6.init..79_3352_msm_cpe_lsm_init) ;
		*(.initcall6.init..105_475_rmnet_perf_init) ;
		*(.initcall6.init..109_198_rmnet_shs_module_init) ;
		*(.initcall6.init..126_339_sock_diag_init) ;
		*(.initcall6.init..124_153_sockev_client_init) ;
		*(.initcall6.init..107_156_llc_init) ;
		*(.initcall6.init..106_113_snap_init) ;
		*(.initcall6.init..107_45_blackhole_init) ;
		*(.initcall6.init..111_272_gact_init_module) ;
		*(.initcall6.init..114_387_mirred_init_module) ;
		*(.initcall6.init..111_273_skbedit_init_module) ;
		*(.initcall6.init..127_1621_htb_module_init) ;
		*(.initcall6.init..108_223_ingress_module_init) ;
		*(.initcall6.init..108_403_prio_module_init) ;
		*(.initcall6.init..108_418_multiq_module_init) ;
		*(.initcall6.init..122_1327_init_u32) ;
		*(.initcall6.init..114_471_init_fw) ;
		*(.initcall6.init..150_726_cls_flow_init) ;
		*(.initcall6.init..142_684_cls_bpf_init_mod) ;
		*(.initcall6.init..109_96_init_em_cmp) ;
		*(.initcall6.init..109_77_init_em_nbyte) ;
		*(.initcall6.init..109_61_init_em_u32) ;
		*(.initcall6.init..133_1011_init_em_meta) ;
		*(.initcall6.init..109_154_init_em_text) ;
		*(.initcall6.init..139_613_nfnetlink_init) ;
		*(.initcall6.init..160_1586_nfnetlink_queue_init) ;
		*(.initcall6.init..141_1161_nfnetlink_log_init) ;
		*(.initcall6.init..142_771_nf_conntrack_standalone_init) ;
		*(.initcall6.init..144_436_nf_ct_proto_gre_init) ;
		*(.initcall6.init..149_3504_ctnetlink_init) ;
		*(.initcall6.init..147_234_nf_conntrack_amanda_init) ;
		*(.initcall6.init..147_610_nf_conntrack_ftp_init) ;
		*(.initcall6.init..144_1881_nf_conntrack_h323_init) ;
		*(.initcall6.init..150_559_nf_conntrack_irc_init) ;
		*(.initcall6.init..145_72_nf_conntrack_netbios_ns_init) ;
		*(.initcall6.init..143_633_nf_conntrack_pptp_init) ;
		*(.initcall6.init..143_219_nf_conntrack_sane_init) ;
		*(.initcall6.init..145_138_nf_conntrack_tftp_init) ;
		*(.initcall6.init..134_213_nf_log_common_init) ;
		*(.initcall6.init..147_863_nf_nat_init) ;
		*(.initcall6.init..141_88_nf_nat_amanda_init) ;
		*(.initcall6.init..141_145_nf_nat_ftp_init) ;
		*(.initcall6.init..141_117_nf_nat_irc_init) ;
		*(.initcall6.init..141_51_nf_nat_tftp_init) ;
		*(.initcall6.init..158_1816_xt_init) ;
		*(.initcall6.init..143_230_tcpudp_mt_init) ;
		*(.initcall6.init..111_84_mark_mt_init) ;
		*(.initcall6.init..144_165_connmark_mt_init) ;
		*(.initcall6.init..137_178_xt_nat_init) ;
		*(.initcall6.init..109_72_classify_tg_init) ;
		*(.initcall6.init..142_142_connsecmark_tg_init) ;
		*(.initcall6.init..137_470_xt_ct_tg_init) ;
		*(.initcall6.init..135_105_log_tg_init) ;
		*(.initcall6.init..137_165_netmap_tg_init) ;
		*(.initcall6.init..108_76_nflog_tg_init) ;
		*(.initcall6.init..132_159_nfqueue_tg_init) ;
		*(.initcall6.init..137_114_redirect_tg_init) ;
		*(.initcall6.init..108_146_secmark_tg_init) ;
		*(.initcall6.init..137_616_tproxy_tg_init) ;
		*(.initcall6.init..140_352_tcpmss_tg_init) ;
		*(.initcall6.init..132_166_tee_tg_init) ;
		*(.initcall6.init..107_52_trace_tg_init) ;
		*(.initcall6.init..130_556_idletimer_tg_init) ;
		*(.initcall6.init..106_374_hardidletimer_tg_init) ;
		*(.initcall6.init..121_154_bpf_mt_init) ;
		*(.initcall6.init..108_44_comment_mt_init) ;
		*(.initcall6.init..145_520_connlimit_mt_init) ;
		*(.initcall6.init..142_329_conntrack_mt_init) ;
		*(.initcall6.init..133_114_dscp_mt_init) ;
		*(.initcall6.init..137_178_ecn_mt_init) ;
		*(.initcall6.init..131_106_esp_mt_init) ;
		*(.initcall6.init..152_1402_hashlimit_mt_init) ;
		*(.initcall6.init..142_98_helper_mt_init) ;
		*(.initcall6.init..131_95_hl_mt_init) ;
		*(.initcall6.init..126_133_iprange_mt_init) ;
		*(.initcall6.init..137_69_length_mt_init) ;
		*(.initcall6.init..108_211_limit_mt_init) ;
		*(.initcall6.init..110_65_mac_mt_init) ;
		*(.initcall6.init..131_178_multiport_mt_init) ;
		*(.initcall6.init..126_127_owner_mt_init) ;
		*(.initcall6.init..131_63_pkttype_mt_init) ;
		*(.initcall6.init..142_185_policy_mt_init) ;
		*(.initcall6.init..108_90_quota_mt_init) ;
		*(.initcall6.init..108_393_quota_mt2_init) ;
		*(.initcall6.init..135_306_socket_mt_init) ;
		*(.initcall6.init..141_77_state_mt_init) ;
		*(.initcall6.init..108_101_statistic_mt_init) ;
		*(.initcall6.init..108_94_string_mt_init) ;
		*(.initcall6.init..103_285_time_mt_init) ;
		*(.initcall6.init..103_117_u32_mt_init) ;
		*(.initcall6.init..132_76_mod_init) ;
		*(.initcall6.init..134_294_gre_offload_init) ;
		*(.initcall6.init..138_1293_sysctl_ipv4_init) ;
		*(.initcall6.init..141_200_gre_init) ;
		*(.initcall6.init..141_724_vti_init) ;
		*(.initcall6.init..145_596_ah4_init) ;
		*(.initcall6.init..141_1054_esp4_init) ;
		*(.initcall6.init..138_197_ipcomp4_init) ;
		*(.initcall6.init..138_114_ipip_init) ;
		*(.initcall6.init..138_152_xfrm4_beet_init) ;
		*(.initcall6.init..139_248_tunnel4_init) ;
		*(.initcall6.init..138_111_xfrm4_transport_init) ;
		*(.initcall6.init..140_150_xfrm4_mode_tunnel_init) ;
		*(.initcall6.init..141_476_nf_conntrack_l3proto_ipv4_init) ;
		*(.initcall6.init..140_456_nf_nat_l3proto_ipv4_init) ;
		*(.initcall6.init..138_161_nf_defrag_init) ;
		*(.initcall6.init..134_390_nf_log_ipv4_init) ;
		*(.initcall6.init..139_628_init) ;
		*(.initcall6.init..141_324_nf_nat_helper_pptp_init) ;
		*(.initcall6.init..140_143_nf_nat_proto_gre_init) ;
		*(.initcall6.init..137_1964_ip_tables_init) ;
		*(.initcall6.init..136_119_iptable_filter_init) ;
		*(.initcall6.init..135_154_iptable_mangle_init) ;
		*(.initcall6.init..138_148_iptable_nat_init) ;
		*(.initcall6.init..132_98_iptable_raw_init) ;
		*(.initcall6.init..135_116_iptable_security_init) ;
		*(.initcall6.init..106_90_ah_mt_init) ;
		*(.initcall6.init..135_143_rpfilter_mt_init) ;
		*(.initcall6.init..141_97_masquerade_tg_init) ;
		*(.initcall6.init..135_112_reject_tg_init) ;
		*(.initcall6.init..130_1682_arp_tables_init) ;
		*(.initcall6.init..128_90_arpt_mangle_init) ;
		*(.initcall6.init..106_99_arptable_filter_init) ;
		*(.initcall6.init..144_1311_inet_diag_init) ;
		*(.initcall6.init..134_188_tcp_diag_init) ;
		*(.initcall6.init..133_302_udp_diag_init) ;
		*(.initcall6.init..135_1129_bbr_register) ;
		*(.initcall6.init..183_2459_bbr_register) ;
		*(.initcall6.init..153_511_cubictcp_register) ;
		*(.initcall6.init..135_302_tcp_westwood_register) ;
		*(.initcall6.init..146_3442_xfrm_user_init) ;
		*(.initcall6.init..144_930_xfrmi_init) ;
		*(.initcall6.init..149_1112_inet6_init) ;
		*(.initcall6.init..146_813_ah6_init) ;
		*(.initcall6.init..142_954_esp6_init) ;
		*(.initcall6.init..140_225_ipcomp6_init) ;
		*(.initcall6.init..145_401_xfrm6_tunnel_init) ;
		*(.initcall6.init..139_191_tunnel6_init) ;
		*(.initcall6.init..138_118_xfrm6_transport_init) ;
		*(.initcall6.init..141_149_xfrm6_mode_tunnel_init) ;
		*(.initcall6.init..140_128_xfrm6_beet_init) ;
		*(.initcall6.init..139_520_mip6_init) ;
		*(.initcall6.init..135_1978_ip6_tables_init) ;
		*(.initcall6.init..130_113_ip6table_filter_init) ;
		*(.initcall6.init..133_148_ip6table_mangle_init) ;
		*(.initcall6.init..126_91_ip6table_raw_init) ;
		*(.initcall6.init..140_464_nf_conntrack_l3proto_ipv6_init) ;
		*(.initcall6.init..138_156_nf_defrag_init) ;
		*(.initcall6.init..135_422_nf_log_ipv6_init) ;
		*(.initcall6.init..136_152_rpfilter_mt_init) ;
		*(.initcall6.init..135_124_reject_tg6_init) ;
		*(.initcall6.init..145_1238_vti6_tunnel_init) ;
		*(.initcall6.init..154_1943_sit_init) ;
		*(.initcall6.init..157_2340_ip6_tunnel_init) ;
		*(.initcall6.init..158_4733_packet_init) ;
		*(.initcall6.init..142_3930_ipsec_pfkey_init) ;
		*(.initcall6.init..136_280_br_init) ;
		*(.initcall6.init..151_2506_ebtables_init) ;
		*(.initcall6.init..126_102_ebtable_broute_init) ;
		*(.initcall6.init..164_1927_l2tp_init) ;
		*(.initcall6.init..148_1925_pppol2tp_init) ;
		*(.initcall6.init..144_699_l2tp_ip_init) ;
		*(.initcall6.init..132_1067_l2tp_nl_init) ;
		*(.initcall6.init..142_402_l2tp_eth_init) ;
		*(.initcall6.init..144_833_l2tp_ip6_init) ;
		*(.initcall6.init..173_1622_sctp_init) ;
		*(.initcall6.init..158_520_sctp_diag_init) ;
		*(.initcall6.init..58_321_init_dns_resolver) ;
		*(.initcall6.init..73_123_qcom_smd_qrtr_driver_init) ;
	}
	.initcall6s.init : {
		*(.initcall6s.init..103_5192_arm_smmu_legacy_bus_init) ;
		*(.initcall6s.init..70_258_deferred_probe_initcall) ;
	}
	.initcall7.init : {
		*(.initcall7.init..81_506_init_oops_id) ;
		*(.initcall7.init..86_944_pm_qos_power_init) ;
		*(.initcall7.init..65_312_pm_debugfs_init) ;
		*(.initcall7.init..95_2859_printk_late_init) ;
		*(.initcall7.init..65_71_tk_debug_sleep_time_init) ;
		*(.initcall7.init..97_1042_taskstats_init) ;
		*(.initcall7.init..50_189_load_system_certificate_list) ;
		*(.initcall7.init..95_3901_fault_around_debugfs) ;
		*(.initcall7.init..51_54_show_mem_notifier_debugfs_register) ;
		*(.initcall7.init..71_613_vmpressure_global_init) ;
		*(.initcall7.init..111_2854_max_swapfiles_check) ;
		*(.initcall7.init..63_103_check_early_ioremap_leak) ;
		*(.initcall7.init..73_891_init_root_keyring) ;
		*(.initcall7.init..45_569_prandom_init_late) ;
		*(.initcall7.init..116_5393_pci_resource_alignment_sysfs_init) ;
		*(.initcall7.init..113_1657_pci_sysfs_init) ;
		*(.initcall7.init..137_3523_clk_debug_init) ;
		*(.initcall7.init..59_1568_socinfo_init_sysfs) ;
		*(.initcall7.init..63_172_msm_minidump_log_init) ;
		*(.initcall7.init..53_112_msm_rq_stats_init) ;
		*(.initcall7.init..64_142_rpm_smd_debugfs_init) ;
		*(.initcall7.init..141_4537_fastrpc_device_init) ;
		*(.initcall7.init..159_2979_dp_display_init) ;
		*(.initcall7.init..54_205_sde_hw_kcal_ctrl_init) ;
		*(.initcall7.init..71_267_deferred_probe_enable_fn) ;
		*(.initcall7.init..82_752_genpd_power_off_unused) ;
		*(.initcall7.init..119_2622_pm_genpd_debug_init) ;
		*(.initcall7.init..153_2244_ngd_slim_init) ;
		*(.initcall7.init..76_921_gpio_keys_init) ;
		*(.initcall7.init..63_77_rtc_hctosys) ;
		*(.initcall7.init..80_807_msm_vfe_init_module) ;
		*(.initcall7.init..56_335_cpu_boost_init) ;
		*(.initcall7.init..95_1829_lpm_levels_module_init) ;
		*(.initcall7.init..76_3137_qpnp_flash_led_init) ;
		*(.initcall7.init..74_1467_of_fdt_raw_init) ;
		*(.initcall7.init..133_4994_ipa3_wwan_init) ;
		*(.initcall7.init..130_2732_rndis_ipa_init_module) ;
		*(.initcall7.init..140_254_tcp_congestion_default) ;
		*(.initcall7.init..156_1559_ip_auto_config) ;
	}
	.initcall7s.init : {
		*(.initcall7s.init..93_1191_clk_disable_unused) ;
		*(.initcall7s.init..98_4998_regulator_init_complete) ;
		*(.initcall7s.init..56_230_regulator_proxy_consumer_remove_all) ;
		*(.initcall7s.init..54_155_of_free_phandle_cache) ;
		*(.initcall7s.init..53_40_alsa_sound_last_init) ;
	}
	.initcallearly.init : {
		*(.initcallearly.init..68_142_cpu_suspend_init) ;
		*(.initcallearly.init..61_268_asids_init) ;
		*(.initcallearly.init..73_764_spawn_ksoftirqd) ;
		*(.initcallearly.init..116_6475_migration_init) ;
		*(.initcallearly.init..60_1313_srcu_bootup_announce) ;
		*(.initcallearly.init..90_2505_rcu_spawn_core_kthreads) ;
		*(.initcallearly.init..92_3324_rcu_spawn_gp_kthread) ;
		*(.initcallearly.init..94_72_check_cpu_stall_init) ;
		*(.initcallearly.init..104_720_rcu_sysrq_init) ;
		*(.initcallearly.init..54_581_cpu_stop_init) ;
		*(.initcallearly.init..87_174_init_zero_pfn) ;
		*(.initcallearly.init..69_198_its_pci_msi_init) ;
		*(.initcallearly.init..66_172_its_pmsi_init) ;
		*(.initcallearly.init..65_232_init_memory_dump) ;
		*(.initcallearly.init..87_1801_rand_initialize) ;
		*(.initcallearly.init..64_632_cpufreq_times_init) ;
		*(.initcallearly.init..63_40_dummy_timer_register) ;
		*(.initcallearly.init..137_682_initialize_ptr_random) ;
	}
	.initcallrootfs.init : {
		*(.initcallrootfs.init..74_685_populate_rootfs) ;
	}
	.security_initcall.init : {
		*(.security_initcall.init..172_6748_selinux_init) ;
	}
}
